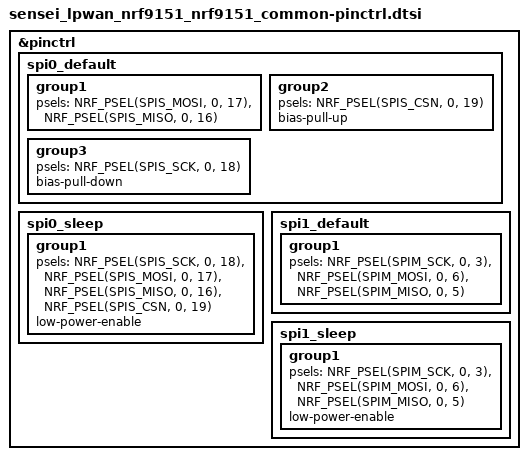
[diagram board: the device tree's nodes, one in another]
// Copyright (c) 2026 ETH Zurich and University of Bologna
// SPDX-License-Identifier: Apache-2.0

/* Pins from the LPWAN shield schematic (see firmware/nrf9151/HARDWARE.md in the firmware repository). */

&pinctrl {
	/* SPIS0: link to the nRF5340 (SPI_A through the TXB0108 level shifter). */
	spi0_default: spi0_default {
		group1 {
			psels = <NRF_PSEL(SPIS_MOSI, 0, 17)>,
				<NRF_PSEL(SPIS_MISO, 0, 16)>;
		};

		/* The level shifter (OE low) leaves SCK and CSN floating while GAP9 owns the bus or the nRF5340 parks its
		 * pins: idle levels are CSN high (not selected) and SCK low (mode 0). */
		group2 {
			psels = <NRF_PSEL(SPIS_CSN, 0, 19)>;
			bias-pull-up;
		};

		group3 {
			psels = <NRF_PSEL(SPIS_SCK, 0, 18)>;
			bias-pull-down;
		};
	};

	spi0_sleep: spi0_sleep {
		group1 {
			psels = <NRF_PSEL(SPIS_SCK, 0, 18)>,
				<NRF_PSEL(SPIS_MOSI, 0, 17)>,
				<NRF_PSEL(SPIS_MISO, 0, 16)>,
				<NRF_PSEL(SPIS_CSN, 0, 19)>;
			low-power-enable;
		};
	};

	/* SPIM1: LR1121. The chip select is a GPIO (P0.01). */
	spi1_default: spi1_default {
		group1 {
			psels = <NRF_PSEL(SPIM_SCK, 0, 3)>,
				<NRF_PSEL(SPIM_MOSI, 0, 6)>,
				<NRF_PSEL(SPIM_MISO, 0, 5)>;
		};
	};

	spi1_sleep: spi1_sleep {
		group1 {
			psels = <NRF_PSEL(SPIM_SCK, 0, 3)>,
				<NRF_PSEL(SPIM_MOSI, 0, 6)>,
				<NRF_PSEL(SPIM_MISO, 0, 5)>;
			low-power-enable;
		};
	};
};
